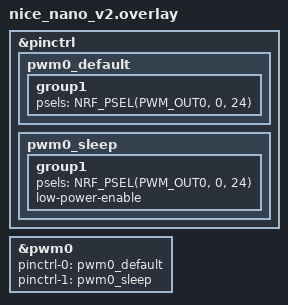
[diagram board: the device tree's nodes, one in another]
/*
 * FT Dongle Test - pinout dla nice!nano v2
 * BL backlight -> D5 -> P0.24 -> PWM0 channel 0
 */

&pinctrl {
    pwm0_default: pwm0_default {
        group1 {
            psels = <NRF_PSEL(PWM_OUT0, 0, 24)>;
        };
    };

    pwm0_sleep: pwm0_sleep {
        group1 {
            psels = <NRF_PSEL(PWM_OUT0, 0, 24)>;
            low-power-enable;
        };
    };
};

&pwm0 {
    status = "okay";
    pinctrl-0 = <&pwm0_default>;
    pinctrl-1 = <&pwm0_sleep>;
    pinctrl-names = "default", "sleep";
};
